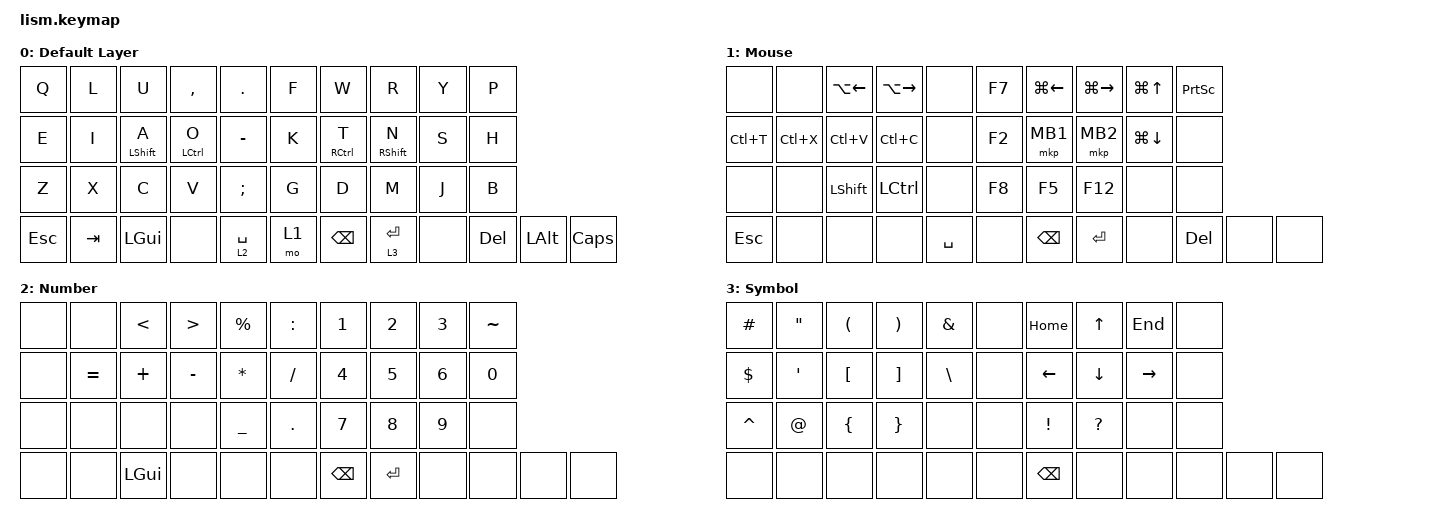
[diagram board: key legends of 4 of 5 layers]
#define ZMK_POINTING_DEFAULT_SCRL_VAL 200

#include <behaviors.dtsi>
#include <dt-bindings/zmk/bt.h>
#include <dt-bindings/zmk/keys.h>
#include <dt-bindings/zmk/pointing.h>
#include <dt-bindings/zmk/mouse.h>

&mt {
    tapping-term-ms = <300>;
    flavor = "balanced";
};

&lt {
    quick-tap-ms = <300>;
};


/ {
    macros {
        emoji: emoji_macro {
            compatible = "zmk,behavior-macro";
            label = "EMOJI";
            #binding-cells = <0>;
            bindings = 
                <&macro_press &kp CAPSLOCK>,
                <&macro_tap &kp E>,
                <&macro_release &kp CAPSLOCK>;
        };
    };
combos {
        compatible = "zmk,combos";

        combo_eisu {
            timeout-ms = <50>;
            key-positions = <12 13>;
            bindings = <&kp LANG2>;
        };

        combo_kana {
            timeout-ms = <50>;
            key-positions = <16 17>;
            bindings = <&kp LANG1>;
        };
    };


    behaviors {
        encoder_msc: sensor_rotate_msc {
            compatible = "zmk,behavior-sensor-rotate-var";
            #sensor-binding-cells = <2>;
            bindings = <&msc>, <&msc>;
            tap-ms = <20>;
        };

        encoder_kp: sensor_rotate_kp {
            compatible = "zmk,behavior-sensor-rotate-var";
            #sensor-binding-cells = <2>;
            bindings = <&kp>, <&kp>;
        };
    };

    keymap {
        compatible = "zmk,keymap";

default_layer {
    display-name = "Default Layer";

    bindings = <
        &kp Q    &kp L        &kp U         &kp COMMA     &kp DOT             &kp F       &kp W        &kp R         &kp Y      &kp P
        &kp E    &kp I   &mt LSHIFT A  &mt LCTRL O   &kp MINUS           &kp K       &mt RCTRL T  &mt RSHIFT N       &kp S &kp H
        &kp Z    &kp X        &kp C         &kp V         &kp SEMI            &kp G       &kp D        &kp M         &kp J      &kp B
        &kp ESC  &kp TAB      &kp LGUI      &none         &lt 2 SPACE         &mo 1       &kp BSPC     &lt 3 ENTER    &none      &kp DEL    &kp LALT   &kp CAPSLOCK
    >;

    sensor-bindings = <&encoder_msc SCRL_UP SCRL_DOWN>;
};

       layer_1 {
    display-name = "Mouse";

    bindings = <
        &none      &none      &kp LA(LEFT)  &kp LA(RIGHT)  &none      &kp F7    &kp LG(LEFT)  &kp LG(RIGHT)  &kp LG(UP)     &kp PSCRN
        &kp LC(T)  &kp LC(X)  &kp LC(V)     &kp LC(C)      &none      &kp F2    &mkp MB1      &mkp MB2       &kp LG(DOWN)     &none
        &none      &none      &kp LSHIFT    &kp LCTRL      &none      &kp F8    &kp F5        &kp F12        &none     &none
        &kp ESC    &none      &none         &none          &kp SPACE  &none     &kp BSPC  &kp ENTER     &none          &kp DEL   &none     &none     
    >;
        };

       layer_2 {
    display-name = "Number";

    bindings = <
        &none          &none          &kp LT        &kp GT        &kp PERCENT      &kp COLON      &kp N1         &kp N2         &kp N3         &kp TILDE
        &none          &kp EQUAL      &kp PLUS      &kp MINUS     &kp ASTERISK     &kp SLASH      &kp N4         &kp N5         &kp N6         &kp N0
        &none          &none          &none         &none         &kp UNDER            &kp DOT        &kp N7         &kp N8         &kp N9         &none
        &none          &none          &kp LGUI         &none         &none            &none          &kp BSPC       &kp ENTER      &none          &none          &none          &none          
    >;

            sensor-bindings = <&encoder_kp C_VOL_UP C_VOL_DN>;
        };

       layer_3 {
    display-name = "Symbol";

    bindings = <
        &kp HASH   &kp DQT   &kp LPAR  &kp RPAR  &kp AMPS   &none      &kp HOME     &kp UP     &kp END      &none
        &kp DLLR   &kp SQT   &kp LBKT  &kp RBKT  &kp BSLH   &none      &kp LEFT  &kp DOWN   &kp RIGHT   &none
        &kp CARET  &kp AT    &kp LBRC  &kp RBRC  &none      &none      &kp EXCL  &kp QMARK  &none      &none
        &none      &none     &none     &none     &none      &none      &kp BSPC   &none     &none      &none      &none      &none      
    >;

        };

        layer_4 {
            display-name = "Device Layer";
            bindings = <
                &none            &none              &none                 &none                   &bt BT_CLR                                             &bt BT_SEL 0   &bt BT_SEL 1     &bt BT_SEL 2       &bt BT_SEL 3        &bt BT_SEL 4
                &none            &none              &none                 &none                   &none                                                  &none          &none            &none              &none               &none
                &sys_reset       &none              &none                 &none                   &none                                                  &none          &none            &none              &none               &sys_reset
                &bootloader      &bt BT_CLR_ALL     &none                 &none                   &none             &none               &studio_unlock   &none          &none            &none              &none               &bootloader
                                                    &trans                &trans                  &trans                                                 &trans         &trans           &trans
            >;
        };

        layer_5 {
            status = "reserved";
            display-name = "Brank Layer";
            bindings = <
                &trans           &trans             &trans                &trans                  &trans                                                 &trans       &trans           &trans             &trans              &trans
                &trans           &trans             &trans                &trans                  &trans                                                 &trans       &trans           &trans             &trans              &trans
                &trans           &trans             &trans                &trans                  &trans                                                 &trans       &trans           &trans             &trans              &trans
                &trans           &trans             &trans                &trans                  &trans            &trans              &trans           &trans       &trans           &trans             &trans              &trans
                                                    &trans                &trans                  &trans                                                 &trans       &trans           &trans
            >;
        };

        layer_6 {
            status = "reserved";
            display-name = "Brank Layer";
            bindings = <
                &trans           &trans             &trans                &trans                  &trans                                                 &trans       &trans           &trans             &trans              &trans
                &trans           &trans             &trans                &trans                  &trans                                                 &trans       &trans           &trans             &trans              &trans
                &trans           &trans             &trans                &trans                  &trans                                                 &trans       &trans           &trans             &trans              &trans
                &trans           &trans             &trans                &trans                  &trans            &trans              &trans           &trans       &trans           &trans             &trans              &trans
                                                    &trans                &trans                  &trans                                                 &trans       &trans           &trans
            >;
        };

        layer_7 {
            status = "reserved";
            display-name = "Brank Layer";
            bindings = <
                &trans           &trans             &trans                &trans                  &trans                                                 &trans       &trans           &trans             &trans              &trans
                &trans           &trans             &trans                &trans                  &trans                                                 &trans       &trans           &trans             &trans              &trans
                &trans           &trans             &trans                &trans                  &trans                                                 &trans       &trans           &trans             &trans              &trans
                &trans           &trans             &trans                &trans                  &trans            &trans              &trans           &trans       &trans           &trans             &trans              &trans
                                                    &trans                &trans                  &trans                                                 &trans       &trans           &trans
            >;
        };
    };

};
